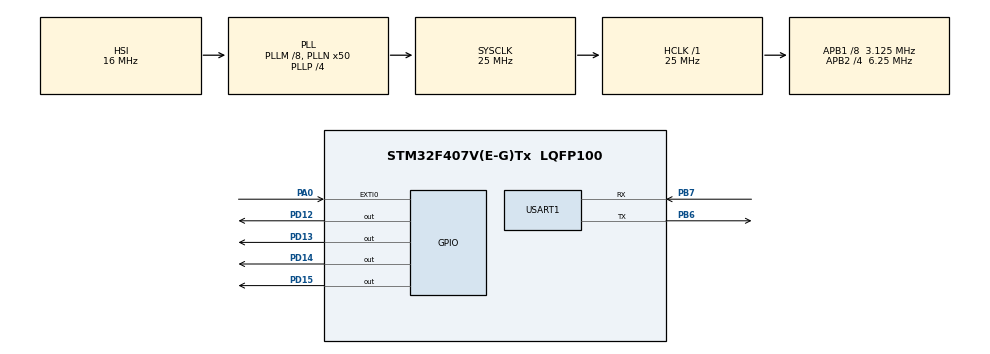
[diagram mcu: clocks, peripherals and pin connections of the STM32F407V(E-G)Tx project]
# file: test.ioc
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Mcu.Family=STM32F4
Mcu.Name=STM32F407V(E-G)Tx
Mcu.Package=LQFP100
NVIC.EXTI0_IRQn=true\:0\:0\:false\:false\:true\:true\:true
NVIC.PriorityGroup=NVIC_PRIORITYGROUP_0
NVIC.TIM3_IRQn=true\:0\:0\:false\:false\:true\:true\:true
PA0-WKUP.Signal=GPXTI0
PB6.Mode=Asynchronous
PB6.Signal=USART1_TX
PB7.Mode=Asynchronous
PB7.Signal=USART1_RX
PD12.Signal=GPIO_Output
PD13.Signal=GPIO_Output
PD14.Signal=GPIO_Output
PD15.Signal=GPIO_Output
ProjectManager.HeapSize=0x200
ProjectManager.StackSize=0x400
ProjectManager.TargetToolchain=MDK-ARM V5
RCC.48MHZClocksFreq_Value=14285714.285714285
RCC.AHBFreq_Value=25000000
RCC.APB1CLKDivider=RCC_HCLK_DIV8
RCC.APB1Freq_Value=3125000
RCC.APB1TimFreq_Value=6250000
RCC.APB2CLKDivider=RCC_HCLK_DIV4
RCC.APB2Freq_Value=6250000
RCC.APB2TimFreq_Value=12500000
RCC.CortexFreq_Value=25000000
RCC.HCLKFreq_Value=25000000
RCC.HSE_VALUE=8000000
RCC.HSI_VALUE=16000000
RCC.LSE_VALUE=32768
RCC.PLLM=8
RCC.PLLN=50
RCC.PLLP=RCC_PLLP_DIV4
RCC.PLLQ=7
RCC.SYSCLKFreq_VALUE=25000000
RCC.SYSCLKSource=RCC_SYSCLKSOURCE_PLLCLK
RCC.VCOOutputFreq_Value=100000000
TIM3.Period=624
TIM3.Prescaler=9999
USART1.VirtualMode=VM_ASYNC
VP_TIM3_VS_ClockSourceINT.Mode=Internal
board=STM32F4DISCOVERY

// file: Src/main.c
/* USER CODE BEGIN Header */
/**
  ******************************************************************************
  * @file           : main.c
  * @brief          : Main program body
  ******************************************************************************
  * @attention
  *
  * <h2><center>&copy; Copyright (c) 2019 STMicroelectronics.
  * All rights reserved.</center></h2>
  *
  * This software component is licensed by ST under BSD 3-Clause license,
  * the "License"; You may not use this file except in compliance with the
  * License. You may obtain a copy of the License at:
  *                        opensource.org/licenses/BSD-3-Clause
  *
  ******************************************************************************
  */
/* USER CODE END Header */

#include "main.h"

/* USER CODE BEGIN Includes */
#include "string.h"
/* USER CODE END Includes */

TIM_HandleTypeDef htim3;

UART_HandleTypeDef huart1;

void SystemClock_Config(void);
static void MX_GPIO_Init(void);
static void MX_USART1_UART_Init(void);
static void MX_TIM3_Init(void);

int main(void)
{
  /* USER CODE BEGIN 1 */
	char* buffTx = "Hello world!\r\n";
  /* USER CODE END 1 */

  /* MCU Configuration--------------------------------------------------------*/

  /* Reset of all peripherals, Initializes the Flash interface and the Systick. */
  HAL_Init();

  /* Configure the system clock */
  SystemClock_Config();

  /* Initialize all configured peripherals */
  MX_GPIO_Init();
  MX_USART1_UART_Init();
  MX_TIM3_Init();
  /* USER CODE BEGIN 2 */
	HAL_TIM_Base_Start_IT(&htim3);
	HAL_GPIO_TogglePin(GPIOD, GPIO_PIN_12);
  /* USER CODE END 2 */

  /* Infinite loop */
  while (1)
  {

    /* USER CODE BEGIN 3 */
		HAL_UART_Transmit(&huart1, (uint8_t*) buffTx, strlen(buffTx), 10);
		HAL_Delay(1000);
  }
  /* USER CODE END 3 */
}

void SystemClock_Config(void)
{
  RCC_OscInitTypeDef RCC_OscInitStruct = {0};
  RCC_ClkInitTypeDef RCC_ClkInitStruct = {0};

  /** Configure the main internal regulator output voltage
  */
  __HAL_RCC_PWR_CLK_ENABLE();
  __HAL_PWR_VOLTAGESCALING_CONFIG(PWR_REGULATOR_VOLTAGE_SCALE1);
  /** Initializes the CPU, AHB and APB busses clocks
  */
  RCC_OscInitStruct.OscillatorType = RCC_OSCILLATORTYPE_HSI;
  RCC_OscInitStruct.HSIState = RCC_HSI_ON;
  RCC_OscInitStruct.HSICalibrationValue = RCC_HSICALIBRATION_DEFAULT;
  RCC_OscInitStruct.PLL.PLLState = RCC_PLL_ON;
  RCC_OscInitStruct.PLL.PLLSource = RCC_PLLSOURCE_HSI;
  RCC_OscInitStruct.PLL.PLLM = 8;
  RCC_OscInitStruct.PLL.PLLN = 50;
  RCC_OscInitStruct.PLL.PLLP = RCC_PLLP_DIV4;
  RCC_OscInitStruct.PLL.PLLQ = 7;
  if (HAL_RCC_OscConfig(&RCC_OscInitStruct) != HAL_OK)
  {
    Error_Handler();
  }
  /** Initializes the CPU, AHB and APB busses clocks
  */
  RCC_ClkInitStruct.ClockType = RCC_CLOCKTYPE_HCLK|RCC_CLOCKTYPE_SYSCLK
                              |RCC_CLOCKTYPE_PCLK1|RCC_CLOCKTYPE_PCLK2;
  RCC_ClkInitStruct.SYSCLKSource = RCC_SYSCLKSOURCE_PLLCLK;
  RCC_ClkInitStruct.AHBCLKDivider = RCC_SYSCLK_DIV1;
  RCC_ClkInitStruct.APB1CLKDivider = RCC_HCLK_DIV8;
  RCC_ClkInitStruct.APB2CLKDivider = RCC_HCLK_DIV4;

  if (HAL_RCC_ClockConfig(&RCC_ClkInitStruct, FLASH_LATENCY_0) != HAL_OK)
  {
    Error_Handler();
  }
}

static void MX_TIM3_Init(void)
{

  TIM_ClockConfigTypeDef sClockSourceConfig = {0};
  TIM_MasterConfigTypeDef sMasterConfig = {0};

  htim3.Instance = TIM3;
  htim3.Init.Prescaler = 9999;
  htim3.Init.CounterMode = TIM_COUNTERMODE_UP;
  htim3.Init.Period = 624;
  htim3.Init.ClockDivision = TIM_CLOCKDIVISION_DIV1;
  htim3.Init.AutoReloadPreload = TIM_AUTORELOAD_PRELOAD_DISABLE;
  if (HAL_TIM_Base_Init(&htim3) != HAL_OK)
  {
    Error_Handler();
  }
  sClockSourceConfig.ClockSource = TIM_CLOCKSOURCE_INTERNAL;
  if (HAL_TIM_ConfigClockSource(&htim3, &sClockSourceConfig) != HAL_OK)
  {
    Error_Handler();
  }
  sMasterConfig.MasterOutputTrigger = TIM_TRGO_RESET;
  sMasterConfig.MasterSlaveMode = TIM_MASTERSLAVEMODE_DISABLE;
  if (HAL_TIMEx_MasterConfigSynchronization(&htim3, &sMasterConfig) != HAL_OK)
  {
    Error_Handler();
  }
  /* USER CODE BEGIN TIM3_Init 2 */
	HAL_TIM_Base_Start(&htim3);
  /* USER CODE END TIM3_Init 2 */

}

static void MX_USART1_UART_Init(void)
{

  huart1.Instance = USART1;
  huart1.Init.BaudRate = 115200;
  huart1.Init.WordLength = UART_WORDLENGTH_8B;
  huart1.Init.StopBits = UART_STOPBITS_1;
  huart1.Init.Parity = UART_PARITY_NONE;
  huart1.Init.Mode = UART_MODE_TX_RX;
  huart1.Init.HwFlowCtl = UART_HWCONTROL_NONE;
  huart1.Init.OverSampling = UART_OVERSAMPLING_16;
  if (HAL_UART_Init(&huart1) != HAL_OK)
  {
    Error_Handler();
  }

}

static void MX_GPIO_Init(void)
{
  GPIO_InitTypeDef GPIO_InitStruct = {0};

  /* GPIO Ports Clock Enable */
  __HAL_RCC_GPIOA_CLK_ENABLE();
  __HAL_RCC_GPIOD_CLK_ENABLE();
  __HAL_RCC_GPIOB_CLK_ENABLE();

  /*Configure GPIO pin Output Level */
  HAL_GPIO_WritePin(GPIOD, GPIO_PIN_12|GPIO_PIN_13|GPIO_PIN_14|GPIO_PIN_15, GPIO_PIN_RESET);

  /*Configure GPIO pin : PA0 */
  GPIO_InitStruct.Pin = GPIO_PIN_0;
  GPIO_InitStruct.Mode = GPIO_MODE_IT_RISING;
  GPIO_InitStruct.Pull = GPIO_NOPULL;
  HAL_GPIO_Init(GPIOA, &GPIO_InitStruct);

  /*Configure GPIO pins : PD12 PD13 PD14 PD15 */
  GPIO_InitStruct.Pin = GPIO_PIN_12|GPIO_PIN_13|GPIO_PIN_14|GPIO_PIN_15;
  GPIO_InitStruct.Mode = GPIO_MODE_OUTPUT_PP;
  GPIO_InitStruct.Pull = GPIO_NOPULL;
  GPIO_InitStruct.Speed = GPIO_SPEED_FREQ_LOW;
  HAL_GPIO_Init(GPIOD, &GPIO_InitStruct);

  /* EXTI interrupt init*/
  HAL_NVIC_SetPriority(EXTI0_IRQn, 0, 0);
  HAL_NVIC_EnableIRQ(EXTI0_IRQn);

}

void Error_Handler(void)
{
}

/************************ (C) COPYRIGHT STMicroelectronics *****END OF FILE****/
